# WBZ450 register map
Vendor: Microchip
Registers are 32-bit, read-write, reset 0x0 unless marked. A register's access mark holds for its fields unless they carry their own. Addresses are absolute, and some are shared; only a register's first bit layout is shown; [hi:lo] are bit positions; {n}, {i} and the like mark numbered series.

## CONFIG — Configuration words, addresses in FusesSpace
0x45E80 ALTFBCFG7 reset 0xFFFFFFFF
  [31:0] ALTFBCFG7 — RESERVED
0x45E84 ALTFBCFG6 reset 0xFFFFFFFF
  [31:0] ALTFBCFG6 — RESERVED
0x45E88 ALTFUSERID reset 0xFFFF
  [31:0] ALTFUSERID — ALT USERID
0x45E8C ALTDEVCFG4 reset 0x840E4000
  [31:0] ALTDEVCFG4 — ALT CFGCON4 Fuses
0x45E90 ALTDEVCFG2 reset 0x5F74FF38
  [31:0] ALTDEVCFG2 — ALT CFGCON2 Fuses
0x45E94 ALTDEVCFG1 reset 0x1410443B
  [31:0] ALTDEVCFG1 — ALT CFGCON1 Fuses
0x45E98 ALTDEVCFG0 reset 0x7100000B
  [31:0] ALTDEVCFG0 — ALT CFGCON0 Fuses
0x45E9C ALTFBCFG0 reset 0x80000002
  [31:0] ALTFBCFG0 — ALT NVR BCFG0
0x45EB0 ALTFCPN3 reset 0xFFFFFFFF
  [31:0] ALTFCPN3 — RESERVED
0x45EB4 ALTFCPN2 reset 0xFFFFFFFF
  [31:0] ALTFCPN2 — RESERVED
0x45EB8 ALTFCPN1 reset 0xFFFFFFFF
  [31:0] ALTFCPN1 — RESERVED
0x45EBC ALTFCPN0 reset 0x10000000
  [31:0] ALTFCPN0 — ALT NVR CPN Register
0x45F80 FBCFG7 reset 0xFFFFFFFF
  [31:0] FBCFG7 — RESERVED
0x45F84 FBCFG6 reset 0xFFFFFFFF
  [31:0] FBCFG6 — RESERVED
0x45F88 FUSERID reset 0xFFFF
  [15:0] USER_ID — User unique ID, readable using the JTAG USER_ID instruction
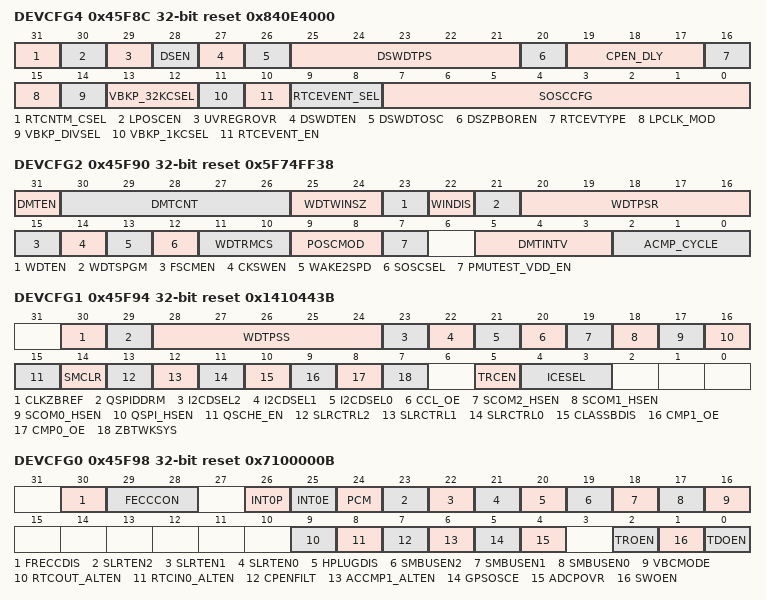
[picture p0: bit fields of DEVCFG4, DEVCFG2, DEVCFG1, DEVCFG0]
0x45F8C DEVCFG4 reset 0x840E4000
  [31] RTCNTM_CSEL — RTC Counter Mode Clock Select
    1=RAW (Raw 32kHz clock); 0=PROCESSED (Processed 32kHz clock)
  [30] LPOSCEN — Low Power (Secondary) Oscillator Enable
    1=ON (Enabled); 0=OFF (Disable)
  [29] UVREGROVR — ULPVREG Retention Mode Override
    1=FORCED (ULPVREG forced in retention mode); 0=CONTROLLED (ULPVREG controlled by XDS/DS FSM)
  [28] DSEN — Deep Sleep Bit Enable
    1=ON (Enable DS Bit in DSCON); 0=OFF (Disable DS Bit in DSCON)
  [27] DSWDTEN — Deep Sleep Watchdog Timer Enable
    1=ON (Enabled); 0=OFF (Disabled)
  [26] DSWDTOSC — Deep Sleep Watchdog Timer Reference Clock Select
    0=SOSC (Select SOSC as DSWDT Reference Clock); 1=LPRC (Select LPRC as DSWDT Reference Clock)
  [25:21] DSWDTPS — Deep Sleep Watchdog Timer Postscale Select
    0=DSPS5 (1:32(1ms)); 1=DSPS6 (1:64(2.1ms)); 2=DSPS7 (1:128(4.1ms)); 3=DSPS8 (1:256(8.3ms)); 4=DSPS9 (1:512(16.5ms)); 5=DSPS10 (1:1024(33ms)); 6=DSPS11 (1:2048(66.1ms)); 7=DSPS12 (1:4096(132.1ms)); 8=DSPS13 (1:8192(264.3ms)); 9=DSPS14 (1:16384(528.5ms)); 10=DSPS15 (1:32768(1.057s)); 11=DSPS16 (1:65536(2.114s)); 12=DSPS17 (1:2^17(4.288s)); 13=DSPS18 (1:2^18(8.456s)); 14=DSPS19 (1:2^19(16.912s)); 15=DSPS20 (1:2^20(33.825s)); 16=DSPS21 (1:2^21(67.7s)); 17=DSPS22 (1:2^22(135.3s)); 18=DSPS23 (1:2^23(4.5 minutes)); 19=DSPS24 (1:2^24(9.0 minutes)); 20=DSPS25 (1:2^25(18.0 minutes)); 21=DSPS26 (1:2^26(36.1 minutes)); 22=DSPS27 (1:2^27(72.2 minutes)); 23=DSPS28 (1:2^28(2.4 hours)); 24=DSPS29 (1:2^29(4.8 hours)); 25=DSPS30 (1:2^30(9.6 hours)); 26=DSPS31 (1:2^31(19.2 hours)); 27=DSPS32 (1:2^32(38.5 hours)); 28=DSPS33 (1:2^33(77.0 hours)); 29=DSPS34 (1:2^34(6.4 days)); 30=DSPS35 (1:2^35(12.8 days)); 31=DSPS36 (1:2^36(25.7 days))
  [20] DSZPBOREN — Deep Sleep Zero-Power BOR Enable
    1=ON (Enabled); 0=OFF (Disabled)
  [19:17] CPEN_DLY — Charge-pump ready digital delay
    {v}=_{v+1}_LPRC ({v+1} LPRC Clock Cycle Delay) (v=0..7)
  [16] RTCEVTYPE — RTC Event Type
    1=EVENT (RTC_EVENT); 0=OUT (RTC_OUT)
  [15] LPCLK_MOD — LPCLK modifier in counter/delay mode
    0=DIV_1 (Divide-by 1 (Recommended when LPCLK=32kHz)); 1=DIV_1_024 (Divide-by 1.024 (Recommended when LPCLK=32.768kHz))
  [14] VBKP_DIVSEL — VDDBUKPCORE LPCLK Clock Divider Selection
    1=DIV_31_25 (Divide by 31.25 (Recommended when LPCLK=32kHz)); 0=DIV_32 (Divide-by 32 (Recommended when LPCLK=32.768kHz)))
  [13:12] VBKP_32KCSEL — VDDBUKPCORE 32kHz clock source selection
    0=FRC; 1=POSC; 2=SOSC; 3=LPRC
  [11] VBKP_1KCSEL — VDDBUKPCORE LPCLK Clock Selection
    1=_1K (Divide by 32 or 31.25 clock depending on VBKP_DIVSEL); 0=_32K (32kHz low power clock)
  [10] RTCEVENT_EN — Pad Output Enable for MCHP legacy RTC event output
    1=ON (Enable RTC Event); 0=OFF (Disable RTC Event)
  [9:8] RTCEVENT_SEL — RTC Event Selection
    0=ONE_SEC (1-Second Clock); 1=ALARM_PULSE; 1=_32_KHZ (32 kHz Clock)
  [7:0] SOSCCFG — SOSC Configuration
0x45F90 DEVCFG2 reset 0x5F74FF38
  [31] DMTEN — Dead Man Timer Enable
    1=ON; 0=OFF
  [30:26] DMTCNT — Dead Man Timer Count Select
    0=DMT8 (2^8 (256)); 1=DMT9 (2^9 (512)); 2=DMT10 (2^10 (1024)); 3=DMT11 (2^11 (2048)); 4=DMT12 (2^12 (4096)); 5=DMT13 (2^13 (8192)); 6=DMT14 (2^14 (16384)); 7=DMT15 (2^15 (32768)); 8=DMT16 (2^16 (65536)); 9=DMT17 (2^17 (131072)); 10=DMT18 (2^18 (262144)); 11=DMT19 (2^19 (524288)); 12=DMT20 (2^20 (1048576)); 13=DMT21 (2^21 (2097152)); 14=DMT22 (2^22 (4194304)); 15=DMT23 (2^23 (8388608)); 16=DMT24 (2^24 (16777216)); 17=DMT25 (2^25 (33554432)); 18=DMT26 (2^26 (67108864)); 19=DMT27 (2^27 (134217728)); 20=DMT28 (2^28 (268435456)); 21=DMT29 (2^29 (536870912)); 22=DMT30 (2^30 (1073741824)); 23=DMT31 (2^31 (2147483648))
  [25:24] WDTWINSZ — Watchdog Timer Window Size
    3=WINSZ_25 (Window size is 25%); 2=WINSZ_37 (Window size is 37.5%); 1=WINSZ_50 (Window size is 50%); 0=WINSZ_75 (Window size is 75%)
  [23] WDTEN — Watchdog Timer Enable
    1=ON; 0=OFF
  [22] WINDIS — Windowed Watchdog Timer Disable
    1=NORMAL; 0=WINDOW
  [21] WDTSPGM — Watchdog Timer Stop during Flash Programming
    1=STOPS; 0=RUNS
  [20:16] WDTPSR — Watchdog Timer Post-scale Select Run
    0=PS1 (1:1); 1=PS2 (1:2); 2=PS4 (1:4); 3=PS8 (1:8); 4=PS16 (1:16); 5=PS32 (1:32); 6=PS64 (1:64); 7=PS128 (1:128); 8=PS256 (1:256); 9=PS512 (1:512); 10=PS1024 (1:1024); 11=PS2048 (1:2048); 12=PS4096 (1:4096); 13=PS8192 (1:8192); 14=PS16384 (1:16384); 15=PS32768 (1:32768); 16=PS65536 (1:65536); 17=PS131072 (1:131072); 18=PS262144 (1:262144); 19=PS524288 (1:524288); 20=PS1048576 (1:1048576)
  [15] FSCMEN — Fail-Safe Clock Monitor Enable
    1=ON; 0=OFF
  [14] CKSWEN — Software Clock Switching Enable
    1=ON; 0=OFF
  [13] WAKE2SPD — 2-Speed startup enabled in Sleep mode
    1=ON; 0=OFF
  [12] SOSCSEL — SOSC Selection Configuration
    1=XTAL; 0=SCLKI
  [11:10] WDTRMCS — WDT RUN Mode Clock Select
    3=LPRC; 0=SYSCLK
  [9:8] POSCMOD — Primary Oscillator Configuration
    3=OFF; 0=HS
  [7] PMUTEST_VDD_EN — PMU Test Output or VDD/2 Enable via ADC IE12
    1=PMU (PMU Test Output Monitor); 0=VDD_DIV_2 (VDD_div_2 Monitor)
  [5:3] DMTINTV — Dead Man Timer Count Window Interval
    0=WIN_0 (Window/Interval value is zero); 1=WIN_1_2 (Window/Interval value is 1/2 counter value); 2=WIN_3_4 (Window/Interval value is 3/4 counter value); 3=WIN_7_8 (Window/Interval value is 7/8 counter value); 4=WIN_15_16 (Window/Interval value is 15/16 counter value); 5=WIN_31_32 (Window/Interval value is 31/32 counter value); 6=WIN_63_64 (Window/Interval value is 63/64 counter value); 7=WIN_127_128 (Window/Interval value is 127/128 counter value)
  [2:0] ACMP_CYCLE — AC Comparator Result Wait Cycles
    0=_32US; 1=_64US; 2=_96US; 3=_128US; 4=_160US; 5=_196US; 6=_224US; 7=_256US
0x45F94 DEVCFG1 reset 0x1410443B
  [30] CLKZBREF — External Reference Clock ZB Enable
    1=ON; 0=OFF
  [29] QSPIDDRM — QSPI DDR Mode Clock Enable
    1=ON; 0=OFF
  [28:24] WDTPSS — Watchdog Timer Post-scale Select Sleep
    0=PSS1 (1:1); 1=PSS2 (1:2); 2=PSS4 (1:4); 3=PSS8 (1:8); 4=PSS16 (1:16); 5=PSS32 (1:32); 6=PSS64 (1:64); 7=PSS128 (1:128); 8=PSS256 (1:256); 9=PSS512 (1:512); 10=PSS1024 (1:1024); 11=PSS2048 (1:2048); 12=PSS4096 (1:4096); 13=PSS8192 (1:8192); 14=PSS16384 (1:16384); 15=PSS32768 (1:32768); 16=PSS65536 (1:65536); 17=PSS131072 (1:131072); 18=PSS262144 (1:262144); 19=PSS524288 (1:524288); 20=PSS1048576 (1:1048576)
  [23] I2CDSEL2 — I2C Delay Select for SERCOM2
    0=OFF; 1=ON
  [22] I2CDSEL1 — I2C Delay Select for SERCOM1
    0=OFF; 1=ON
  [21] I2CDSEL0 — I2C Delay Select for SERCOM0
    0=OFF; 1=ON
  [20] CCL_OE — CCL Pads (via PPS) Output Enable
    0=OFF; 1=ON
  [19] SCOM2_HSEN — SERCOM2 Direct (High Speed) Pin Enable
    0=PPS; 1=DIRECT
  [18] SCOM1_HSEN — SERCOM1 Direct (High Speed) Pin Enable
    0=PPS; 1=DIRECT
  [17] SCOM0_HSEN — SERCOM0 Direct (High Speed) Pin Enable
    0=PPS; 1=DIRECT
  [16] QSPI_HSEN — QSPI Direct (High Speed) Pin Enable
    0=PPS; 1=DIRECT
  [15] QSCHE_EN — QSPI Address Space Cache Attribute
    0=OFF; 1=ON
  [14] SMCLR — Selects CRU handling of MCLR Control
    1=NO_POR; 0=FAUX_POR
  [13] SLRCTRL2 — I2C Slew Rate Control for SERCOM2
    0=GPIO; 1=SERCOM
  [12] SLRCTRL1 — I2C Slew Rate Control for SERCOM1
    0=GPIO; 1=SERCOM
  [11] SLRCTRL0 — I2C Slew Rate Control for SERCOM0
    0=GPIO; 1=SERCOM
  [10] CLASSBDIS — Disable CLASSB Device Functionality
    0=ON; 1=OFF
  [9] CMP1_OE — Analog Comparator-1 Output Enable
    0=OFF; 1=ON
  [8] CMP0_OE — Analog Comparator-0 Output Enable
    0=OFF; 1=ON
  [7] ZBTWKSYS — ZBT Subsystem External Wake-up source
    0=OFF; 1=ON
  [5] TRCEN — Trace Enable
    0=OFF; 1=ON
  [4:3] ICESEL — EMUC/EMUD Communication Channel Select
    0=PGC4_PGD4; 1=NOT_USED; 2=PGC2_PGD2; 3=PGC1_PGD1
0x45F98 DEVCFG0 reset 0x7100000B
  [30] FRECCDIS — Flex RAM ECC Control
    1=OFF; 0=ON
  [29:28] FECCCON — Flash ECC Control
    0=ON; 1=DYNAMIC; 3=OFF
  [26] INT0P — INT0P Polarity
    0=NEG; 1=POS
  [25] INT0E — INT0 Enable
    0=OFF; 1=ON
  [24] PCM — PCHE I/D Cacheable Mode
    0=CPU; 1=SFR
  [23] SLRTEN2 — SLRT Enable for SERCOM2
    0=OFF; 1=ON
  [22] SLRTEN1 — SLRT Enable for SERCOM1
    0=OFF; 1=ON
  [21] SLRTEN0 — SLRT Enable for SERCOM0
    0=OFF; 1=ON
  [20] HPLUGDIS — Hot Plugging Disable
    0=OFF; 1=ON
  [19] SMBUSEN2 — SMBus Enable for SERCOM2
    0=OFF; 1=ON
  [18] SMBUSEN1 — SMBus Enable for SERCOM1
    0=OFF; 1=ON
  [17] SMBUSEN0 — SMBus Enable for SERCOM0
    0=OFF; 1=ON
  [16] VBCMODE — VBC Operating Mode
    0=DIRECT; 1=INDIR
  [9] RTCOUT_ALTEN — RTCOUT Alternate Enable
    0=PA4; 1=PA10
  [8] RTCIN0_ALTEN — RTCIN0 Alternate Enable
    0=PA3; 1=PA9
  [7] CPENFILT — ADC CP Filter Enable
    0=OFF; 1=ON
  [6] ACCMP1_ALTEN — AC CMP1 Alternate Enable
    1=PA6; 0=PA1
  [5] GPSOSCE — GPIO/SOSC Enable
    0=GPIO; 1=SOSC
  [4] ADCPOVR — ADC Charge Pump Override
    0=HW; 1=SW
  [2] TROEN — Trace Output Enable
    0=OFF; 1=ON
  [1] SWOEN — SWO enable on 2-wire debug interface
    0=OFF; 1=ON
  [0] TDOEN — TDO enable for 2-wire JTAG
    0=OFF; 1=ON
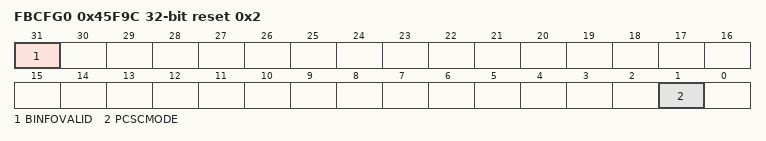
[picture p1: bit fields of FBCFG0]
0x45F9C FBCFG0 reset 0x2
  [31] BINFOVALID — BCFG info valid
    1=NOT_VALID (BCFG0 to BCFG7 is not valid.); 0=VALID (BCFG0 to BCFG7 is valid.)
  [1] PCSCMODE — PCache Single cache Mode
    1=SINGLE (PCHE ICache Only.CPU Instructions (code, data) go to PCHE ONLY.); 0=DUAL (PCHE ICache and DCache. CPU opcodes go to PCEHE ICache port and data goes to PCHE)
0x45FB0 FCPN3 reset 0xFFFFFFFF
  [31:0] FCPN3 — RESERVED
0x45FB4 FCPN2 reset 0xFFFFFFFF
  [31:0] FCPN2 — RESERVED
0x45FB8 FCPN1 reset 0xFFFFFFFF
  [31:0] FCPN1 — RESERVED
0x45FBC FCPN0 reset 0x10000000
  [28] CP — Boot Code Protect
    1=DISABLED (Protection Disabled); 0=ENABLED (Protection Enabled)
